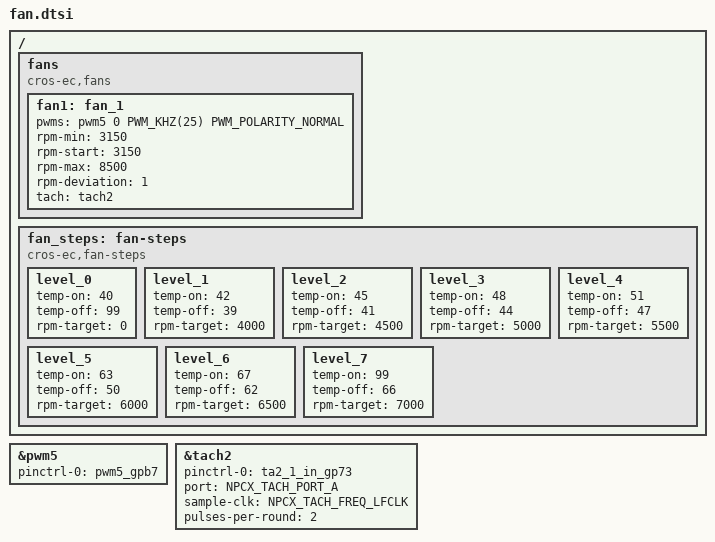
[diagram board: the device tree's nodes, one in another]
/* Copyright 2026 The ChromiumOS Authors
 * Use of this source code is governed by a BSD-style license that can be
 * found in the LICENSE file.
 */

/ {
	fans {
		compatible = "cros-ec,fans";

		fan1: fan_1 {
			pwms = <&pwm5 0 PWM_KHZ(25) PWM_POLARITY_NORMAL>;
			rpm-min = <3150>;
			rpm-start = <3150>;
			rpm-max = <8500>;
			rpm-deviation = <1>;
			tach = <&tach2>;
		};
	};

	fan_steps: fan-steps {
		compatible = "cros-ec,fan-steps";
		level_0 {
			temp-on = <40>;
			temp-off = <99>;
			rpm-target = <0>;
		};
		level_1 {
			temp-on = <42>;
			temp-off = <39>;
			rpm-target = <4000>;
		};
		level_2 {
			temp-on = <45>;
			temp-off = <41>;
			rpm-target = <4500>;
		};
		level_3 {
			temp-on = <48>;
			temp-off = <44>;
			rpm-target = <5000>;
		};
		level_4 {
			temp-on = <51>;
			temp-off = <47>;
			rpm-target = <5500>;
		};
		level_5 {
			temp-on = <63>;
			temp-off = <50>;
			rpm-target = <6000>;
		};
		level_6 {
			temp-on = <67>;
			temp-off = <62>;
			rpm-target = <6500>;
		};
		level_7 {
			temp-on = <99>;
			temp-off = <66>;
			rpm-target = <7000>;
		};
	};
};

&pwm5 {
	status = "okay";
	pinctrl-0 = <&pwm5_gpb7>;
	pinctrl-names = "default";
};

&tach2 {
	status = "okay";
	pinctrl-0 = <&ta2_1_in_gp73>;
	pinctrl-names = "default";
	port = <NPCX_TACH_PORT_A>;
	sample-clk = <NPCX_TACH_FREQ_LFCLK>;
	pulses-per-round = <2>;
};

